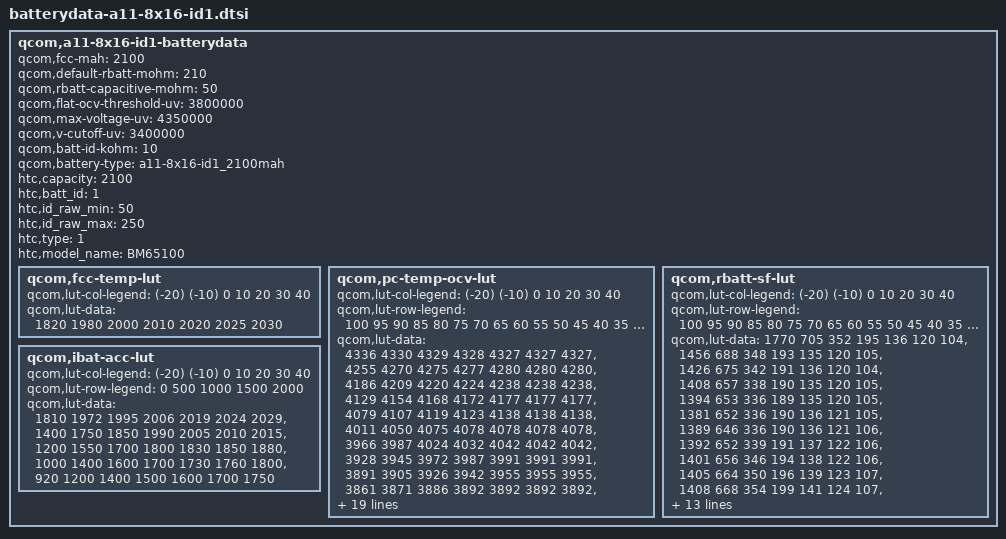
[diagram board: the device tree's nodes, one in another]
/* Copyright (c) 2013, The Linux Foundation. All rights reserved.
 *
 * This program is free software; you can redistribute it and/or modify
 * it under the terms of the GNU General Public License version 2 and
 * only version 2 as published by the Free Software Foundation.
 *
 * This program is distributed in the hope that it will be useful,
 * but WITHOUT ANY WARRANTY; without even the implied warranty of
 * MERCHANTABILITY or FITNESS FOR A PARTICULAR PURPOSE.  See the
 * GNU General Public License for more details.
 */

qcom,a11-8x16-id1-batterydata {
	qcom,fcc-mah = <2100>;
	qcom,default-rbatt-mohm = <210>;
	qcom,rbatt-capacitive-mohm = <50>;
	qcom,flat-ocv-threshold-uv = <3800000>;
	qcom,max-voltage-uv = <4350000>;
	qcom,v-cutoff-uv = <3400000>;
	qcom,batt-id-kohm = <10>;
	qcom,battery-type = "a11-8x16-id1_2100mah";
	htc,capacity = <2100>;
	htc,batt_id = <1>;
	htc,id_raw_min = <50>;
	htc,id_raw_max = <250>;
	htc,type = <1>;
	htc,model_name = "BM65100";

	qcom,fcc-temp-lut {
		qcom,lut-col-legend = <(-20) (-10) 0 10 20 30 40>;
		qcom,lut-data = <1820 1980 2000 2010 2020 2025 2030>;
	};

	qcom,pc-temp-ocv-lut {
		qcom,lut-col-legend = <(-20) (-10) 0 10 20 30 40>;
		qcom,lut-row-legend = <100 95 90 85 80 75 70 65 60 55 50 45 40 35 30 25 20 15 10 9 8 7 6 5 4 3 2 1 0>;
		qcom,lut-data = <4336 4330 4329 4328 4327 4327 4327>,
				<4255 4270 4275 4277 4280 4280 4280>,
				<4186 4209 4220 4224 4238 4238 4238>,
				<4129 4154 4168 4172 4177 4177 4177>,
				<4079 4107 4119 4123 4138 4138 4138>,
				<4011 4050 4075 4078 4078 4078 4078>,
				<3966 3987 4024 4032 4042 4042 4042>,
				<3928 3945 3972 3987 3991 3991 3991>,
				<3891 3905 3926 3942 3955 3955 3955>,
				<3861 3871 3886 3892 3892 3892 3892>,
				<3838 3845 3855 3860 3872 3872 3872>,
				<3822 3824 3831 3836 3840 3840 3840>,
				<3809 3809 3811 3816 3832 3832 3832>,
				<3794 3796 3795 3799 3803 3803 3803>,
				<3779 3781 3783 3784 3792 3792 3792>,
				<3762 3762 3767 3765 3755 3755 3755>,
				<3745 3736 3733 3727 3732 3732 3732>,
				<3723 3709 3701 3695 3712 3712 3712>,
				<3692 3687 3686 3683 3687 3687 3687>,
				<3681 3678 3673 3666 3682 3682 3682>,
				<3670 3670 3661 3648 3672 3672 3672>,
				<3659 3648 3631 3616 3653 3653 3653>,
				<3648 3626 3602 3585 3629 3629 3629>,
				<3638 3590 3560 3539 3595 3595 3595>,
				<3619 3555 3517 3493 3560 3560 3560>,
				<3600 3504 3462 3434 3465 3465 3465>,
				<3581 3453 3406 3376 3410 3410 3410>,
				<3562 3382 3309 3248 3258 3258 3258>,
				<3544 3310 3213 3180 3140 3140 3140>;
	};

	qcom,rbatt-sf-lut {
		qcom,lut-col-legend = <(-20) (-10) 0 10 20 30 40>;
		qcom,lut-row-legend = <100 95 90 85 80 75 70 65 60 55 50 45 40 35 30 25 20 15 10 8 6 4 2 0>;
		qcom,lut-data = <1770 705 352 195 136 120 104>,
						<1456 688 348 193 135 120 105>,
						<1426 675 342 191 136 120 104>,
						<1408 657 338 190 135 120 105>,
						<1394 653 336 189 135 120 105>,
						<1381 652 336 190 136 121 105>,
						<1389 646 336 190 136 121 106>,
						<1392 652 339 191 137 122 106>,
						<1401 656 346 194 138 122 106>,
						<1405 664 350 196 139 123 107>,
						<1408 668 354 199 141 124 107>,
						<1406 678 363 202 142 124 107>,
						<1415 687 372 208 144 126 108>,
						<1438 697 382 213 146 127 108>,
						<1438 702 397 220 150 129 109>,
						<1438 718 407 230 153 131 110>,
						<1438 737 420 242 158 135 112>,
						<1438 750 433 253 165 138 112>,
						<1438 739 440 263 172 143 114>,
						<1438 748 449 268 176 146 116>,
						<1438 765 458 277 180 148 117>,
						<1440 786 472 285 186 152 118>,
						<1446 801 488 297 190 156 122>,
						<1463 834 513 323 208 174 140>;
	};

	qcom,ibat-acc-lut {
		qcom,lut-col-legend = <(-20) (-10) 0 10 20 30 40>;
		qcom,lut-row-legend = <0 500 1000 1500 2000>;
		qcom,lut-data = <1810 1972 1995 2006 2019 2024 2029>,
						<1400 1750 1850 1990 2005 2010 2015>,
						<1200 1550 1700 1800 1830 1850 1880>,
						<1000 1400 1600 1700 1730 1760 1800>,
						<920 1200 1400 1500 1600 1700 1750>;
	};
};
